# R7FA4W1AD register map
Vendor: Renesas; Series: RA4; File version: 1.0
CPU: CM4 r0p1, little endian, MPU, FPU, VTOR, 4 interrupt priority bits
Registers are 8-bit, read-write, reset 0x0 unless marked. A register's access mark holds for its fields unless they carry their own. Offsets are from the block's base; [hi:lo] are bit positions; 'fields as' and 'values as' point back to an identical list.

## MMF — Memory Mirror Function
Base 0x40001000
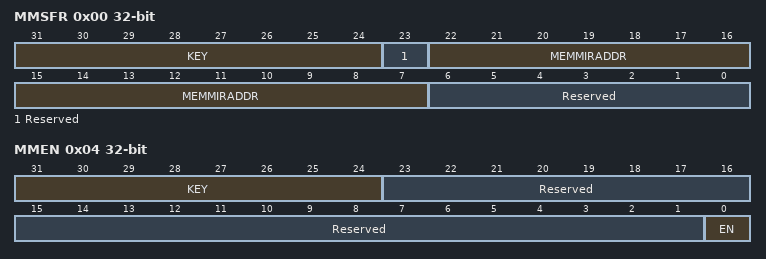
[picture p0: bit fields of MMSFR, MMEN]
0x00 MMSFR 32-bit — MemMirror Special Function Register
  [31:24] KEY wo — MMSFR Key Code
    219=Writing to the MEMMIRADDR bits are valid, when the KEY bits are written 0xDB; other=others (Writing to the MEMMIRADDR bits are invalid.)
  [23] Reserved — This bit is read as 0. The write value should be 0.
  [22:7] MEMMIRADDR — Specifies the memory mirror address.NOTE: A value cannot be set in the low-order 7 bits. These bits are fixed to 0.
  [6:0] Reserved — These bits are read as 0000000. The write value should be 0000000.
0x04 MMEN 32-bit — MemMirror Enable Register
  [31:24] KEY wo — MMEN Key Code
    219=Writing to the EN bit is valid, when the KEY bits are written 0xDB; other=others (Writing to the EN bit is invalid.)
  [23:1] Reserved — These bits are read as 00000000000000000000000. The write value should be 00000000000000000000000.
  [0] EN — Memory Mirror Function Enable
    1=Memory Mirror Function is enabled; 0=Memory Mirror Function is disabled

## WDT — Watchdog Timer
Base 0x40044200
0x00 WDTRR reset 0xFF — WDT Refresh Register
  [7:0] WDTRR — WDTRR is an 8-bit register that refreshes the down-counter of the WDT.
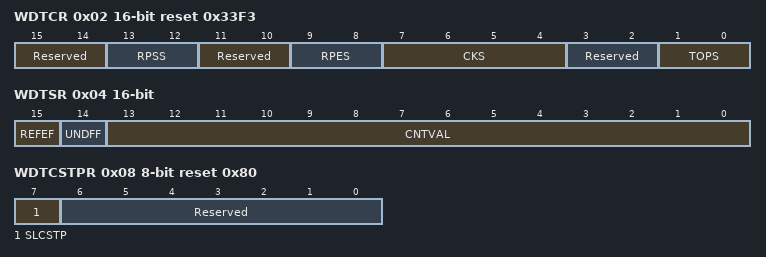
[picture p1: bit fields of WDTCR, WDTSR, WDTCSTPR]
0x02 WDTCR 16-bit reset 0x33F3 — WDT Control Register
  [15:14] Reserved — These bits are read as 00. The write value should be 00.
  [13:12] RPSS — Window Start Position Selection
    0=25 percent; 1=50 percent; 2=75 percent; 3=100 percent (window start position is not specified)
  [11:10] Reserved — These bits are read as 00. The write value should be 00.
  [9:8] RPES — Window End Position Selection
    0=75 percent; 1=50 percent; 2=25 percent; 3=0 percent (window end position is not specified)
  [7:4] CKS — Clock Division Ratio Selection
    1=PCLK/4; 4=PCLK/64; 15=PCLK/128; 6=PCLK/512; 7=PCLK/2048; 8=PCLK/8192; other=others (setting prohibited)
  [3:2] Reserved — These bits are read as 00. The write value should be 00.
  [1:0] TOPS — Timeout Period Selection
    0=1,024 cycles (03FFh); 1=4,096 cycles (0FFFh); 2=8,192 cycles (1FFFh); 3=16,384 cycles (3FFFh)
0x04 WDTSR 16-bit — WDT Status Register
  [15] REFEF write-0-clears read-modifies — Refresh Error Flag
    0=No refresh error occurred; 1=Refresh error occurred
  [14] UNDFF write-0-clears read-modifies — Underflow Flag
    0=No underflow occurred; 1=Underflow occurred
  [13:0] CNTVAL ro — Down-Counter ValueValue counted by the down-counter
0x06 WDTRCR reset 0x80 — WDT Reset Control Register
  [7] RSTIRQS — Reset Interrupt Request Selection
    0=Non-maskable interrupt request or interrupt request output is enabled; 1=Reset output is enabled
0x08 WDTCSTPR reset 0x80 — WDT Count Stop Control Register
  [7] SLCSTP — Sleep-Mode Count Stop Control
    0=Count stop is disabled; 1=Count is stopped at a transition to sleep mode
  [6:0] Reserved — These bits are read as 0000000. The write value should be 0000000.

## IWDT — Independent Watchdog Timer
Base 0x40044400
0x00 IWDTRR reset 0xFF — IWDT Refresh Register
  [7:0] IWDTRR — The counter is refreshed by writing 0x00 and then writing 0xFF to this register.
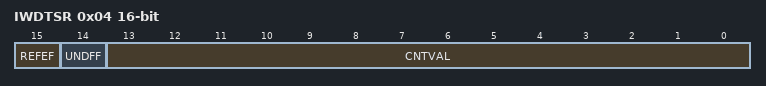
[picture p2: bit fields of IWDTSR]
0x04 IWDTSR 16-bit — IWDT Status Register
  [15] REFEF write-0-clears read-modifies — Refresh Error Flag
    0=Refresh error not occurred; 1=Refresh error occurred
  [14] UNDFF write-0-clears read-modifies — Underflow Flag
    0=Underflow not occurred; 1=Underflow occurred
  [13:0] CNTVAL ro — Counter ValueValue counted by the counter

## PORT0 — Port 0 Control Registers
Base 0x40040000
Same registers: PORT5 0x400400A0, PORT6 0x400400C0, PORT7 0x400400E0, PORT8 0x40040100, PORT9 0x40040120
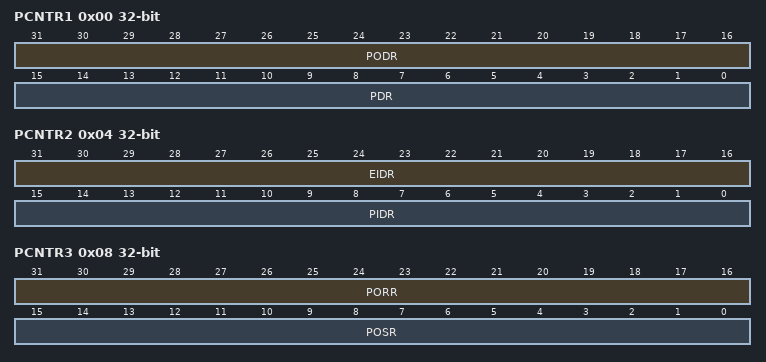
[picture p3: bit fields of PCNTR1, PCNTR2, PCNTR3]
0x00 PCNTR1 32-bit — Port Control Register 1
  [31:16] PODR — Pmn Output Data
    0=Low output; 1=High output
  [15:0] PDR — Pmn Direction
    0=Input (functions as an input pin); 1=Output (functions as an output pin)
0x00 PODR 16-bit (alternate view of PCNTR1) — Output data register
  [15:0] PODR — Pmn Output Data
    0=Low output; 1=High output
0x02 PDR 16-bit (alternate view of PCNTR1) — Data direction register
  [15:0] PDR — Pmn Direction
    values as PCNTR1.PDR
0x04 PCNTR2 32-bit ro (reset mask 0xFFFF0000) — Port Control Register 2
  [31:16] EIDR — Pmn Event Input Data
    0=Low input; 1=High input
  [15:0] PIDR — Pmn Input Data
    0=Low input; 1=High input
0x06 PIDR 16-bit ro reset not defined (alternate view of PCNTR2) — Input data register
  [15:0] PIDR — Pmn Input Data
    0=Low input; 1=High input
0x08 PCNTR3 32-bit wo — Port Control Register 3
  [31:16] PORR — Pmn Output Reset
    0=No affect to output; 1=Low output
  [15:0] POSR — Pmn Output Set
    0=No affect to output; 1=High output
0x08 PORR 16-bit wo (alternate view of PCNTR3) — Output reset register
  [15:0] PORR — Pmn Output Reset
    0=No affect to output; 1=Low output
0x0A POSR 16-bit wo (alternate view of PCNTR3) — Output set register
  [15:0] POSR — Pmn Output Set
    0=No affect to output; 1=High output

## PORT1 — Port 1 Control Registers
Base 0x40040020
Same registers: PORT2 0x40040040, PORT3 0x40040060, PORT4 0x40040080
Registers as PORT0; these are added or differ:
0x04 EIDR 16-bit ro reset not defined (alternate view of PCNTR2) — Event input data register
  [15:0] EIDR — Pmn Event Input Data
    0=Low input; 1=High input
0x08 PORR 16-bit wo (alternate view of PCNTR3) — Output set register
  [15:0] PORR — Pmn Output Reset
    0=No affect to output; 1=Low output
0x0A POSR 16-bit wo (alternate view of PCNTR3) — Output reset register
  [15:0] POSR — Pmn Output Set
    0=No affect to output; 1=High output
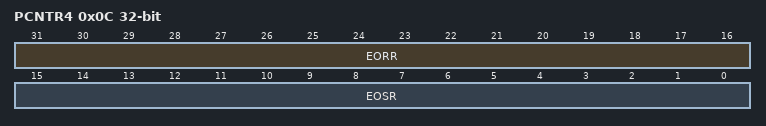
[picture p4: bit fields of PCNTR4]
0x0C PCNTR4 32-bit — Port Control Register 4
  [31:16] EORR — Pmn Event Output Reset
    0=No affect to output; 1=Low output
  [15:0] EOSR — Pmn Event Output Set
    0=No affect to output; 1=High output
0x0C EORR 16-bit (alternate view of PCNTR4) — Event output set register
  [15:0] EORR — Pmn Event Output Reset
    0=No affect to output; 1=Low output
0x0E EOSR 16-bit (alternate view of PCNTR4) — Event output reset register
  [15:0] EOSR — Pmn Event Output Set
    0=No affect to output; 1=High output
